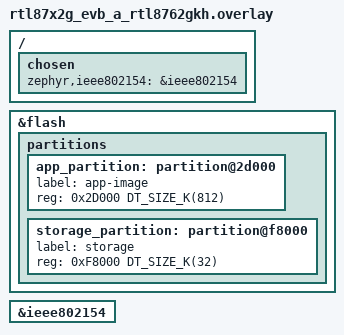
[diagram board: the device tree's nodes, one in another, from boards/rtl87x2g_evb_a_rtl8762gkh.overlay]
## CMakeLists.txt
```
#
# Copyright (c) 2024 Realtek Semiconductor Corp.
#
# SPDX-License-Identifier: Apache-2.0
#
cmake_minimum_required(VERSION 3.20.0)

find_package(Zephyr REQUIRED HINTS $ENV{ZEPHYR_BASE})

project(ot-cli)

target_sources(app PRIVATE src/main.c)
target_sources(app PRIVATE src/alarm.c)
target_link_options(app
    PUBLIC
        -Wl,--wrap,memcpy
        -Wl,--wrap,memset
        -Wl,--wrap,mac_EnterCritical_rom
        -Wl,--wrap,mac_ExitCritical_rom
        -Wl,--wrap,otPlatReset
        -Wl,--wrap,platformAlarmMilliInit
        -Wl,--wrap,platformAlarmMilliProcess
        -Wl,--wrap,otPlatAlarmMilliGetNow
        -Wl,--wrap,otPlatAlarmMilliStartAt
        -Wl,--wrap,otPlatAlarmMilliStop
        -Wl,--wrap,platformAlarmMicroInit
        -Wl,--wrap,platformAlarmMicroProcess
        -Wl,--wrap,otPlatAlarmMicroGetNow
        -Wl,--wrap,otPlatAlarmMicroStartAt
        -Wl,--wrap,otPlatAlarmMicroStop
        -Wl,--wrap,otPlatTimeGet
        -Wl,--wrap,otPlatLog
)
zephyr_code_relocate(FILES src/alarm.c LOCATION ITCM_TEXT)
zephyr_code_relocate(FILES ${ZEPHYR_BASE}/modules/openthread/platform/radio.c LOCATION ITCM_TEXT)
```

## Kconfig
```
menu "Zephyr Kernel"
source "Kconfig.zephyr"
endmenu

module = OT_COMMAND_LINE_INTERFACE
module-str = ot-cli
source "${ZEPHYR_BASE}/subsys/logging/Kconfig.template.log_config"
```

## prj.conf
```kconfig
#CONFIG_LOG=y
CONFIG_MAIN_STACK_SIZE=8192

# driver
#CONFIG_REALTEK_USING_SDK_LIB=y
CONFIG_REALTEK_BEE_EFUSE=y
CONFIG_REALTEK_BEE_MAC_802154=y

# Network shell
CONFIG_SHELL=y
CONFIG_OPENTHREAD_SHELL=y
CONFIG_SHELL_ARGC_MAX=26
CONFIG_SHELL_CMD_BUFF_SIZE=416

# Enable OpenThread features set
CONFIG_OPENTHREAD_THREAD_VERSION_1_3=y
CONFIG_OPENTHREAD_COAP=n
CONFIG_OPENTHREAD_COAPS=n
CONFIG_OPENTHREAD_COMMISSIONER=n
CONFIG_OPENTHREAD_DIAG=y
CONFIG_OPENTHREAD_DNS_CLIENT=y
CONFIG_OPENTHREAD_DHCP6_SERVER=y
CONFIG_OPENTHREAD_DHCP6_CLIENT=y
CONFIG_OPENTHREAD_ECDSA=y
CONFIG_OPENTHREAD_ENABLE_SERVICE=y
CONFIG_OPENTHREAD_EXTERNAL_HEAP=y
CONFIG_OPENTHREAD_IP6_FRAGM=y
CONFIG_OPENTHREAD_JAM_DETECTION=y
CONFIG_OPENTHREAD_JOINER=y
CONFIG_OPENTHREAD_MAC_FILTER=y
CONFIG_OPENTHREAD_NETDIAG_CLIENT=y
CONFIG_OPENTHREAD_RAW=y
CONFIG_OPENTHREAD_SLAAC=y
CONFIG_OPENTHREAD_SNTP_CLIENT=y
CONFIG_OPENTHREAD_SRP_CLIENT=y
CONFIG_OPENTHREAD_UDP_FORWARD=y
CONFIG_OPENTHREAD_DUA=y
CONFIG_OPENTHREAD_MLR=y
CONFIG_OPENTHREAD_LINK_METRICS_INITIATOR=y
CONFIG_OPENTHREAD_LINK_METRICS_SUBJECT=y
CONFIG_OPENTHREAD_CSL_RECEIVER=y
CONFIG_OPENTHREAD_DEBUG=y
CONFIG_OPENTHREAD_LOG_LEVEL_INFO=y
CONFIG_OPENTHREAD_PING_SENDER=y

# Disable Opethread Crypto PSA
#CONFIG_OPENTHREAD_CRYPTO_PSA=n

# Openthread L2
CONFIG_OPENTHREAD_RADIO_WORKQUEUE_STACK_SIZE=2048
CONFIG_OPENTHREAD_MANUAL_START=y
CONFIG_NET_L2_OPENTHREAD=y

# Generic networking options
CONFIG_NETWORKING=y
CONFIG_NET_PKT_TXTIME=y
CONFIG_NET_PKT_TIMESTAMP=y

#CONFIG_MBEDTLS_SHA1_C=n
CONFIG_FPU=y

# Disable ITS/Secure Storage Transformation Settings
#CONFIG_SECURE_STORAGE_ITS_TRANSFORM_AEAD_KEY_PROVIDER_ENTRY_UID_HASH=n
#CONFIG_SECURE_STORAGE_ITS_STORE_IMPLEMENTATION_NONE=n
#CONFIG_SECURE_STORAGE=n


# NVS
CONFIG_NVS=y

# BT
CONFIG_BT=y
```

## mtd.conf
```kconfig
CONFIG_LOG=y

CONFIG_PM_DEVICE=y

CONFIG_OPENTHREAD_MTD=y
CONFIG_OPENTHREAD_MTD_SED=y
CONFIG_OPENTHREAD_CSL_RECEIVER=y

CONFIG_THREAD_MONITOR=y
CONFIG_THREAD_NAME=y
```

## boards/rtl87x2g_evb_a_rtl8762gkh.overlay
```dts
/*
 * Copyright (c) 2024 Realtek Semiconductor Corp.
 *
 * SPDX-License-Identifier: Apache-2.0
 */


&flash {
	partitions {
		/delete-node/ partition@2d000;
		/delete-node/ partition@fc000;

		app_partition: partition@2d000 {
			label = "app-image";
			reg = <0x2D000 DT_SIZE_K(812)>;
		};
		storage_partition: partition@f8000 {
			label = "storage";
			reg = <0xF8000 DT_SIZE_K(32)>;
		};
	};
};

&ieee802154 {
	status = "okay";
};

/ {
	chosen {
		zephyr,ieee802154 = &ieee802154;
	};
};
```

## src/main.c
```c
/*
 * Copyright (c) 2024 Realtek Semiconductor Corp.
 *
 * SPDX-License-Identifier: Apache-2.0
 */

#include <zephyr/kernel.h>
#include <zephyr/logging/log.h>

#include <zephyr/drivers/uart.h>


int main(void)
{
#if DT_NODE_HAS_COMPAT(DT_CHOSEN(zephyr_shell_uart), zephyr_cdc_acm_uart)
	int ret;
	const struct device *dev;
	uint32_t dtr = 0U;

	dev = DEVICE_DT_GET(DT_CHOSEN(zephyr_shell_uart));
	if (dev == NULL) {
		LOG_ERR("Failed to find specific UART device");
		return 0;
	}

	LOG_INF("Waiting for host to be ready to communicate");

	/* Data Terminal Ready - check if host is ready to communicate */
	while (!dtr) {
		ret = uart_line_ctrl_get(dev, UART_LINE_CTRL_DTR, &dtr);
		if (ret) {
			LOG_ERR("Failed to get Data Terminal Ready line state: %d",
				ret);
			continue;
		}
		k_msleep(100);
	}

	/* Data Carrier Detect Modem - mark connection as established */
	(void)uart_line_ctrl_set(dev, UART_LINE_CTRL_DCD, 1);
	/* Data Set Ready - the NCP SoC is ready to communicate */
	(void)uart_line_ctrl_set(dev, UART_LINE_CTRL_DSR, 1);
#endif
	return 0;
}

// replace memcpy, memset
#define CHECK_STR_UNALIGNED(X, Y) \
    (((uint32_t)(X) & (sizeof (uint32_t) - 1)) | \
     ((uint32_t)(Y) & (sizeof (uint32_t) - 1)))

#define STR_OPT_BIGBLOCKSIZE     (sizeof(uint32_t) << 2)

#define STR_OPT_LITTLEBLOCKSIZE (sizeof (uint32_t))

void *__wrap_memcpy(void *s1, const void *s2, size_t n)
{
    char *dst = (char *) s1;
    const char *src = (const char *) s2;

    uint32_t *aligned_dst;
    const uint32_t *aligned_src;

    /* If the size is small, or either SRC or DST is unaligned,
     * then punt into the byte copy loop.  This should be rare.
     */
    if (n < sizeof(uint32_t) || CHECK_STR_UNALIGNED(src, dst))
    {
        while (n--)
        {
            *dst++ = *src++;
        }

        return s1;
    } /* if */

    aligned_dst = (uint32_t *)dst;
    aligned_src = (const uint32_t *)src;

    /* Copy 4X long words at a time if possible.  */
    while (n >= STR_OPT_BIGBLOCKSIZE)
    {
        *aligned_dst++ = *aligned_src++;
        *aligned_dst++ = *aligned_src++;
        *aligned_dst++ = *aligned_src++;
        *aligned_dst++ = *aligned_src++;
        n -= STR_OPT_BIGBLOCKSIZE;
    } /* while */

    /* Copy one long word at a time if possible.  */
    while (n >= STR_OPT_LITTLEBLOCKSIZE)
    {
        *aligned_dst++ = *aligned_src++;
        n -= STR_OPT_LITTLEBLOCKSIZE;
    } /* while */

    /* Pick up any residual with a byte copier.  */
    dst = (char *)aligned_dst;
    src = (const char *)aligned_src;
    while (n--)
    {
        *dst++ = *src++;
    }

    return s1;
} /* _memcpy() */

#define wsize   sizeof(uint32_t)
#define wmask   (wsize - 1)

void *__wrap_memset(void *dst0, int Val, size_t length)
{
    size_t t;
    uint32_t Wideval;
    uint8_t *dst;

    dst = dst0;
    /*
     * If not enough words, just fill bytes.  A length >= 2 words
     * guarantees that at least one of them is `complete' after
     * any necessary alignment.  For instance:
     *
     *  |-----------|-----------|-----------|
     *  |00|01|02|03|04|05|06|07|08|09|0A|00|
     *            ^---------------------^
     *       dst         dst+length-1
     *
     * but we use a minimum of 3 here since the overhead of the code
     * to do word writes is substantial.
     */
    if (length < 3 * wsize)
    {
        while (length != 0)
        {
            *dst++ = Val;
            --length;
        }
        return (dst0);
    }

    if ((Wideval = (uint32_t)Val) != 0)     /* Fill the word. */
    {
        Wideval = ((Wideval << 24) | (Wideval << 16) | (Wideval << 8) | Wideval); /* u_int is 32 bits. */
    }

    /* Align destination by filling in bytes. */
    if ((t = (uint32_t)dst & wmask) != 0)
    {
        t = wsize - t;
        length -= t;
        do
        {
            *dst++ = Val;
        }
        while (--t != 0);
    }

    /* Fill words.  Length was >= 2*words so we know t >= 1 here. */
    t = length / wsize;
    do
    {
        *(uint32_t *)dst = Wideval;
        dst += wsize;
    }
    while (--t != 0);

    /* Mop up trailing bytes, if any. */
    t = length & wmask;
    if (t != 0)
        do
        {
            *dst++ = Val;
        }
        while (--t != 0);

    return (dst0);
}
```

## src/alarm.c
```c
/*
 * Copyright (c) 2024 Realtek Semiconductor Corp.
 *
 * SPDX-License-Identifier: Apache-2.0
 */
#include <zephyr/kernel.h>
#include <zephyr/irq.h>
#include <zephyr/device.h>
#include <zephyr/pm/device.h>
#include <zephyr/pm/policy.h>
#include <string.h>
#include <inttypes.h>
#include <openthread/platform/time.h>
#include <openthread/platform/alarm-milli.h>
#include <openthread/platform/alarm-micro.h>
#include <openthread/platform/diag.h>
#include <openthread/platform/logging.h>
#include <openthread/logging.h>
#include <openthread-system.h>

#include <stdio.h>

#include "platform-zephyr.h"
#include "openthread-core-zephyr-config.h"

#include "mac_driver.h"
#include "mac_driver_mpan.h"
#include "mac_data_type.h"
#include "mac_stats.h"
#include "mac_802154_frame_parser.h"
#include "trace.h"
#include "power_manager_unit_zbmac.h"

extern uint64_t bt_clk_offset;
static bool timer_ms_fired, timer_us_fired;

//------------------------------------------------------------------------------
// Configuration / forward decls
//------------------------------------------------------------------------------

// Minimum ahead-of-time (in us) required to program HW timer; otherwise, fire immediately.
const uint32_t kMinScheduleAdvanceUs = 20;

//------------------------------------------------------------------------------
// State
//------------------------------------------------------------------------------

volatile uint64_t micro_alarm_us[MAX_PAN_NUM];
volatile uint64_t milli_alarm_us[MAX_PAN_NUM];
void micro_handler(uint8_t pan_idx);
void milli_handler(uint8_t pan_idx);

extern void (*zbmac_pm_init)(zbpm_adapter_t *padapter);
static zbpm_adapter_t zbpm_adap;
static bool zbpm_inited = false;

static void pm_init(void)
{
	if (true == zbpm_inited)
	{
		return;
	}

	zbpm_inited = true;
	mac_power_manager_init(&zbpm_adap, NULL, NULL);
}

static void zbpm_enter_pan0(void)
{
}

static void zbpm_enter_pan1(void)
{
}

extern void mac_notify_pm_wakeup(uint8_t pan_idx);
static void zbpm_exit_pan0(void)
{
    zbpm_adapter_t *padapter = &zbpm_adap;
    uint32_t curr_us;
    mac_bt_clk_t bt_clk_overflow_value =
    {
        .bt_clk_counter = 0,        /*!< [9..0] BT clock counter in 1 us unit */
        .bt_native_clk = 0x3FFFFF   /*!< [31..10] BT native clock[21:1] in unit of BT slot */
    };

    curr_us = mac_GetCurrentBTUS();
    if (curr_us < padapter->enter_time_us)
    {
        bt_clk_offset += MAX_BT_CLOCK_COUNTER;
    }
    mac_SetBTClkInt(MAC_BT_TIMER3, &bt_clk_overflow_value);
    mac_notify_pm_wakeup(0);
}

static void zbpm_exit_pan1(void)
{
    zbpm_adapter_t *padapter = &zbpm_adap;
    uint32_t curr_us;
    mac_bt_clk_t bt_clk_overflow_value =
    {
        .bt_clk_counter = 0,        /*!< [9..0] BT clock counter in 1 us unit */
        .bt_native_clk = 0x3FFFFF   /*!< [31..10] BT native clock[21:1] in unit of BT slot */
    };

    curr_us = mac_GetCurrentBTUS();
    if (curr_us < padapter->enter_time_us)
    {
        bt_clk_offset += MAX_BT_CLOCK_COUNTER;
    }
    mac_SetBTClkInt(MAC_BT_TIMER3, &bt_clk_overflow_value);
    mac_notify_pm_wakeup(1);
}

void mac_report_pm_wakeup(uint8_t pan_idx)
{
    micro_handler(pan_idx);
    milli_handler(pan_idx);
}

void BEE_SleepProcess(uint8_t pan_idx)
{
#if defined(CONFIG_OPENTHREAD_MTD)
    volatile zbpm_adapter_t *padapter = &zbpm_adap;
    uint64_t now;
    uint32_t now_btus;
    uint32_t s;
    uint32_t diff;

    if (false == zbpm_inited)
    {
        return;
    }

    s = irq_lock();
    now_btus = mac_GetCurrentBTUS();
    now = bt_clk_offset + now_btus;

    // Get the next valid (non-zero) alarm time among milli, micro, and tx_backoff
    uint64_t tmp_ms = (milli_alarm_us[pan_idx] > now) ? milli_alarm_us[pan_idx] : 0;
    uint64_t tmp_us = (micro_alarm_us[pan_idx] > now) ? micro_alarm_us[pan_idx] : 0;

    /*if (!tmp_ms && !tmp_us)
    {
        os_unlock(s);
        goto stay_awake;
    }*/

    // Default: use micro alarm if available
    diff = tmp_us ? tmp_us - now : UINT32_MAX;

    // If milli alarm is valid and triggers at least 1 ms earlier than micro alarm, use milli alarm instead
    if (tmp_ms && (!tmp_us || tmp_us > tmp_ms + 1000))
    {
        diff = tmp_ms - now;
    }

    if (diff < 10000)
    {
        irq_unlock(s);
        goto stay_awake;
    }

    if (diff > ((MAX_BT_CLOCK_COUNTER >> 1) - 1))
    {
        diff = (MAX_BT_CLOCK_COUNTER >> 1) - 1;
    }

    padapter->cfg.wake_interval_en = 0;
    padapter->cfg.stage_time_learned = 0;
    padapter->wakeup_time_us = now_btus + diff;
    padapter->wakeup_interval_us = 0;

    padapter->enter_callback = (pan_idx == 0) ? zbpm_enter_pan0 : zbpm_enter_pan1;
    padapter->exit_callback = (pan_idx == 0) ? zbpm_exit_pan0 : zbpm_exit_pan1;

    padapter->wakeup_reason = ZBMAC_PM_WAKEUP_UNKNOWN;
    padapter->error_code = ZBMAC_PM_ERROR_UNKNOWN;
    padapter->power_mode = ZBMAC_DEEP_SLEEP;
    //otLogNotePlat("sleep %u us tmp_us %llu", diff, tmp_us);

    irq_unlock(s);
    return;

stay_awake:
    s = irq_lock();
    if (padapter->power_mode == ZBMAC_DEEP_SLEEP)
    {
        padapter->power_mode = ZBMAC_ACTIVE;
    }
    irq_unlock(s);
#endif
}

//------------------------------------------------------------------------------
// Fast 64-bit arithmetic helpers (avoid __aeabi_uldiv / __aeabi_lmul in Flash)
//------------------------------------------------------------------------------

/**
 * 64-bit divide by 1000 using only HW 32-bit UDIV instructions.
 * Splits into three 32-bit divisions via long-division with 16-bit digits.
 */
static inline uint64_t div_1000(uint64_t x)
{
    uint32_t lo = (uint32_t)x;
    uint32_t hi = (uint32_t)(x >> 32);

    if (hi == 0)
    {
        return lo / 1000;
    }

    uint32_t q_hi = hi / 1000;
    uint32_t r_hi = hi % 1000;

    uint32_t mid = (r_hi << 16) | (lo >> 16);
    uint32_t q_mid = mid / 1000;
    uint32_t r_mid = mid % 1000;

    uint32_t bot = (r_mid << 16) | (lo & 0xFFFF);
    uint32_t q_lo = bot / 1000;

    return ((uint64_t)q_hi << 32) | ((uint64_t)q_mid << 16) | q_lo;
}

//------------------------------------------------------------------------------
// Common helpers
//------------------------------------------------------------------------------

typedef enum
{
    kAlarmMicro = 0,
    kAlarmMilli = 1,
} AlarmKind;

/**
 * Select HW timer ID based on PAN index and alarm kind.
 */
static inline uint32_t SelectTimerId(uint8_t pan_idx, AlarmKind kind)
{
    return (kind == kAlarmMicro) ? MAC_BT_TIMER1 : MAC_BT_TIMER0;
}

/**
 * Fire the corresponding alarm event immediately.
 */
static inline void FireAlarmNow(AlarmKind kind, uint8_t pan_idx)
{
    if (kind == kAlarmMicro)
    {
        timer_us_fired = true;
    }
    else
    {
        timer_ms_fired = true;
    }
    otSysEventSignalPending();
}

/**
 * Schedule an alarm or fire immediately if too close.
 * Returns true if scheduled; false if fired immediately.
 */

static bool ScheduleOrFire(AlarmKind kind,
                           otInstance *aInstance,
                           uint8_t     pan_idx,
                           uint64_t    target_us,
                           uint64_t    now_us,
                           uint32_t    curr_hw_us)
{
    uint32_t diff = 0;

    if (target_us > now_us)
    {
        uint64_t delta = target_us - now_us;
        diff           = (delta > UINT32_MAX) ? UINT32_MAX : (uint32_t)delta;
    }

    if (diff > kMinScheduleAdvanceUs)
    {
        const uint32_t tid = SelectTimerId(pan_idx, kind);
        mac_SetBTClkUSInt(tid, curr_hw_us + diff);
        // otLogNotePlat("%s set %u us", (kind == kAlarmMicro) ? "us" : "ms", diff);
        BEE_SleepProcess(pan_idx);
        return true;
    }

    // Too close in time: fire immediately.
    FireAlarmNow(kind, pan_idx);
    return false;
}

//------------------------------------------------------------------------------
// Platform API
//------------------------------------------------------------------------------

void micro_handler(uint8_t pan_idx)
{
    // Guard: only signal if an alarm is armed for this PAN.
    if (micro_alarm_us[pan_idx] > 0)
    {
        FireAlarmNow(kAlarmMicro, pan_idx);
    }
}

uint32_t __wrap_otPlatAlarmMicroGetNow(void)
{
    // Truncate to 32-bit microseconds as per OT platform API.
    return (uint32_t)otPlatTimeGet();
}

void __wrap_otPlatAlarmMicroStartAt(otInstance *aInstance, uint32_t t0, uint32_t dt)
{
    uint8_t pan_idx = 0;

    uint32_t s       = irq_lock();
    uint32_t curr_us = mac_GetCurrentBTUS();
    uint64_t now_us  = bt_clk_offset + curr_us;

    // Convert (t0, dt) to absolute 64-bit microsecond timestamp.
    uint64_t target_us = mac_ConvertT0AndDtTo64BitTime(t0, dt, &now_us);
    micro_alarm_us[pan_idx] = target_us;

    (void)ScheduleOrFire(kAlarmMicro, aInstance, pan_idx, target_us, now_us, curr_us);
    irq_unlock(s);
}

void __wrap_otPlatAlarmMicroStop(otInstance *aInstance)
{
    uint8_t pan_idx = 0;
    OT_UNUSED_VARIABLE(aInstance);

    // Disarm: handler will ignore spurious IRQs afterwards.
    micro_alarm_us[pan_idx] = 0;
    BEE_SleepProcess(pan_idx);
}

void milli_handler(uint8_t pan_idx)
{
    if (milli_alarm_us[pan_idx] > 0)
    {
        FireAlarmNow(kAlarmMilli, pan_idx);
    }
}

uint32_t __wrap_otPlatAlarmMilliGetNow(void)
{
    // Convert microseconds to milliseconds as per API contract.
    return (uint32_t)div_1000(otPlatTimeGet());
}

void __wrap_otPlatAlarmMilliStartAt(otInstance *aInstance, uint32_t t0, uint32_t dt)
{
    uint8_t pan_idx = 0;

    uint32_t s       = irq_lock();
    uint32_t curr_us = mac_GetCurrentBTUS();
    uint64_t now_us  = bt_clk_offset + curr_us;

    // For milli alarm, original logic converts using millisecond base.
    uint64_t now_ms    = div_1000(now_us);
    uint64_t target_ms = mac_ConvertT0AndDtTo64BitTime(t0, dt, &now_ms);
    uint64_t target_us = target_ms * 1000;
    milli_alarm_us[pan_idx] = target_us;

    (void)ScheduleOrFire(kAlarmMilli, aInstance, pan_idx, target_us, now_us, curr_us);
    irq_unlock(s);
}

void __wrap_otPlatAlarmMilliStop(otInstance *aInstance)
{
    uint8_t pan_idx = 0;
    OT_UNUSED_VARIABLE(aInstance);

    milli_alarm_us[pan_idx] = 0;
    BEE_SleepProcess(pan_idx);
}

uint64_t __wrap_otPlatTimeGet(void)
{
    uint32_t s = irq_lock();
    uint64_t now = bt_clk_offset + mac_GetCurrentBTUS();
    irq_unlock(s);
    return now;
}

void __wrap_platformAlarmMilliInit(void)
{
    //DBG_DIRECT("%s %d", __func__, __LINE__);
    mpan_RegisterTimer(0, MAC_BT_TIMER0, (mac_irq_callback_t)milli_handler, 0);
    mpan_RegisterSleepHandler(BEE_SleepProcess);
    pm_init();
}

void __wrap_platformAlarmMicroInit(void)
{
    //DBG_DIRECT("%s %d", __func__, __LINE__);
    mpan_RegisterTimer(0, MAC_BT_TIMER1, (mac_irq_callback_t)micro_handler, 0);
}

void __wrap_platformAlarmMilliProcess(otInstance *aInstance)
{
    uint8_t pan_idx = 0;

    if (timer_ms_fired) {
	timer_ms_fired = false;
    milli_alarm_us[pan_idx] = 0;
	otPlatAlarmMilliFired(aInstance);
    }
}

void __wrap_platformAlarmMicroProcess(otInstance *aInstance)
{
    uint8_t pan_idx = 0;

    if (timer_us_fired) {
	timer_us_fired = false;
    micro_alarm_us[pan_idx] = 0;
	otPlatAlarmMicroFired(aInstance);
    }
}

// replace misc.c
extern void WDG_SystemReset(int wdt_mode, int reset_reason);
void __wrap_otPlatReset(otInstance *aInstance)
{
    DBG_DIRECT("%s", __func__);
    WDG_SystemReset(0, 0xff);
}

// replace logging.c
void __wrap_otPlatLog(otLogLevel aLogLevel, otLogRegion aLogRegion, const char *aFormat, ...)
{
	ARG_UNUSED(aLogRegion);
	uint8_t l_msg[116];
    va_list ap;
    va_start(ap, aFormat);
    vsnprintf(l_msg, 116, aFormat, ap);
    va_end(ap);
    DBG_DIRECT("%s", l_msg);
}
```
